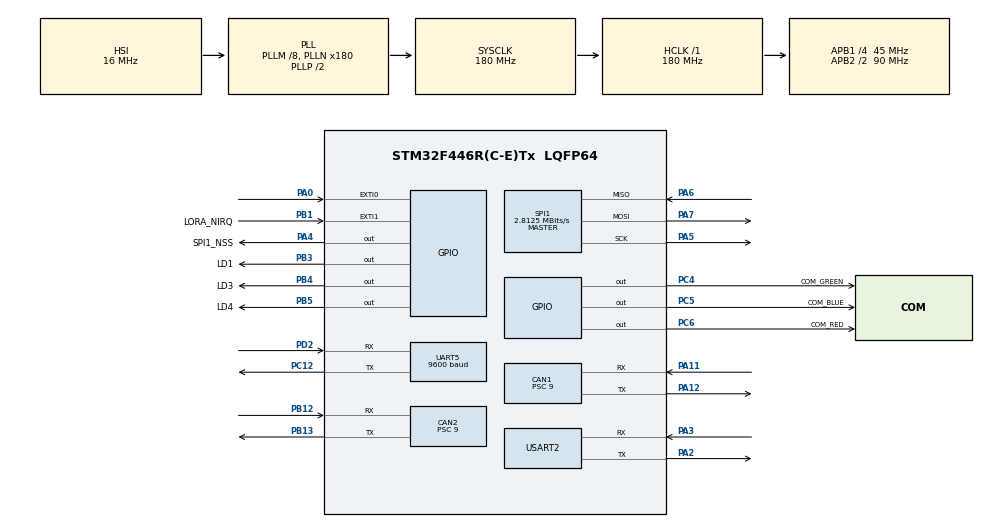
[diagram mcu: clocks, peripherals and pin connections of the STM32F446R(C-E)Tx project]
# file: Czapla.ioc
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Mcu.Family=STM32F4
PA6.Mode=Full_Duplex_Master
PH0-OSC_IN.Signal=RCC_OSC_IN
RCC.CortexFreq_Value=180000000
Dma.SPI1_RX.1.Mode=DMA_NORMAL
Dma.SPI1_RX.1.FIFOMode=DMA_FIFOMODE_ENABLE
SPI1.VirtualType=VM_MASTER
Dma.SPI1_RX.1.FIFOThreshold=DMA_FIFO_THRESHOLD_FULL
PC12.Signal=UART5_TX
PA14.GPIO_Label=TCK
Dma.UART5_RX.0.FIFOMode=DMA_FIFOMODE_DISABLE
PC6.GPIO_Label=COM_RED
PA11.Mode=Master
PB13.Signal=CAN2_TX
RCC.SYSCLKSource=RCC_SYSCLKSOURCE_PLLCLK
ProjectManager.StackSize=0x400
VP_TIM1_VS_no_output1.Mode=Output Compare1 No Output
PA12.Signal=CAN1_TX
TIM1.Prescaler=44999
Dma.SPI1_RX.1.PeriphInc=DMA_PINC_DISABLE
SPI1.Direction=SPI_DIRECTION_2LINES
RCC.HCLKFreq_Value=180000000
RCC.APB2TimFreq_Value=180000000
Dma.UART5_RX.0.Priority=DMA_PRIORITY_LOW
SPI1.CalculateBaudRate=2.8125 MBits/s
UART5.OverSampling=UART_OVERSAMPLING_8
RCC.AHBFreq_Value=180000000
PH0-OSC_IN.Mode=HSE-External-Oscillator
RCC.HSE_VALUE=8000000
NVIC.TIM8_TRG_COM_TIM14_IRQn=true\:0\:0\:false\:false\:true\:false\:true
Dma.SPI1_RX.1.Priority=DMA_PRIORITY_LOW
PC14-OSC32_IN.Mode=LSE-External-Oscillator
PC4.GPIO_Label=COM_GREEN
PA14.Mode=Serial_Wire
CAN2.Prescaler=9
Dma.UART5_RX.0.MemDataAlignment=DMA_MDATAALIGN_BYTE
PB1.GPIO_Label=LORA_NIRQ
VP_SYS_VS_tim14.Mode=TIM14
Dma.SPI1_RX.1.MemBurst=DMA_MBURST_SINGLE
VP_TIM1_VS_ClockSourceINT.Mode=Internal
Dma.SPI1_RX.1.Direction=DMA_PERIPH_TO_MEMORY
RCC.FLatency-AdvancedSettings=FLASH_LATENCY_5
PH1-OSC_OUT.Mode=HSE-External-Oscillator
CAN1.Prescaler=9
Mcu.Package=LQFP64
PB1.Signal=GPXTI1
PA6.Signal=SPI1_MISO
PB12.Mode=Slave
NVIC.TimeBase=TIM8_TRG_COM_TIM14_IRQn
TIM1.Pulse-Output\ Compare1\ No\ Output=Ttransfer-1
CAN2.BS1=CAN_BS1_6TQ
CAN2.BS2=CAN_BS2_6TQ
USART2.VirtualMode=VM_ASYNC
NVIC.TimeBaseIP=TIM14
RCC.APB2CLKDivider=RCC_HCLK_DIV2
PB5.GPIO_Label=LD4
NVIC.DMA2_Stream2_IRQn=true\:0\:0\:false\:false\:true\:false\:true
Dma.Request1=SPI1_RX
RCC.APB1TimFreq_Value=90000000
NVIC.DMA1_Stream0_IRQn=true\:0\:0\:false\:false\:true\:false\:true
UART5.BaudRate=9600
PC5.Signal=GPIO_Output
TIM1.Period=2*Ttransfer+2*Tswap-1
PB13.Mode=Slave
Dma.Request0=UART5_RX
SPI1.BaudRatePrescaler=SPI_BAUDRATEPRESCALER_32
Dma.SPI1_RX.1.MemInc=DMA_MINC_ENABLE
PA4.GPIO_Label=SPI1_NSS
PB4.Signal=GPIO_Output
PA3.Signal=USART2_RX
CAN1.CalculateTimeQuantum=200.0
PA5.Mode=Full_Duplex_Master
PB3.GPIO_Label=LD1
Dma.SPI1_RX.1.Instance=DMA2_Stream2
PC15-OSC32_OUT.Mode=LSE-External-Oscillator
Dma.UART5_RX.0.MemInc=DMA_MINC_ENABLE
Dma.UART5_RX.0.Direction=DMA_PERIPH_TO_MEMORY
PA7.Mode=Full_Duplex_Master
Dma.SPI1_RX.1.MemDataAlignment=DMA_MDATAALIGN_BYTE
TIM1.Channel-Output\ Compare1\ No\ Output=TIM_CHANNEL_1
PC6.Signal=GPIO_Output
PC4.Signal=GPIO_Output
UART5.VirtualMode=Asynchronous
RCC.APB1CLKDivider=RCC_HCLK_DIV4
PC14-OSC32_IN.Signal=RCC_OSC32_IN
PA0-WKUP.Signal=GPXTI0
PA13.Signal=SYS_JTMS-SWDIO
PA3.Mode=Asynchronous
CAN1.BS2=CAN_BS2_6TQ
CAN1.BS1=CAN_BS1_6TQ
ProjectManager.TargetToolchain=SW4STM32
RCC.USBFreq_Value=180000000
PC15-OSC32_OUT.Signal=RCC_OSC32_OUT
PD2.Mode=Asynchronous
PA5.Signal=SPI1_SCK
Dma.UART5_RX.0.Mode=DMA_NORMAL
PC12.Mode=Asynchronous
board=NUCLEO-F446RE
RCC.VCOOutputFreq_Value=360000000
Dma.SPI1_RX.1.PeriphBurst=DMA_PBURST_SINGLE
VP_TIM13_VS_ClockSourceINT.Mode=Enable_Timer
RCC.APB2Freq_Value=90000000
PB4.GPIO_Label=LD3
SPI1.Mode=SPI_MODE_MASTER
CAN2.CalculateTimeQuantum=200.0
PH1-OSC_OUT.Signal=RCC_OSC_OUT
PA13.Mode=Serial_Wire
Dma.UART5_RX.0.PeriphDataAlignment=DMA_PDATAALIGN_BYTE
Mcu.Name=STM32F446R(C-E)Tx
PA2.Signal=USART2_TX
PA13.GPIO_Label=TMS
Dma.SPI1_RX.1.PeriphDataAlignment=DMA_PDATAALIGN_BYTE
RCC.48MHZClocksFreq_Value=84000000
PB3.Signal=GPIO_Output
PA4.Signal=GPIO_Output
RCC.SYSCLKFreq_VALUE=180000000
PB5.Signal=GPIO_Output
PA12.Mode=Master
PC5.GPIO_Label=COM_BLUE
Dma.UART5_RX.0.Instance=DMA1_Stream0
PA11.Signal=CAN1_RX
PA14.Signal=SYS_JTCK-SWCLK
ProjectManager.HeapSize=0x200
RCC.HSI_VALUE=16000000
NVIC.TIM8_UP_TIM13_IRQn=true\:0\:0\:false\:false\:true\:true\:true
NVIC.PriorityGroup=NVIC_PRIORITYGROUP_4
RCC.PLLM=8
RCC.PLLN=180
PA2.Mode=Asynchronous
Dma.UART5_RX.0.PeriphInc=DMA_PINC_DISABLE
PD2.Signal=UART5_RX
RCC.APB1Freq_Value=45000000
VP_CRC_VS_CRC.Mode=CRC_Activate
PB12.Signal=CAN2_RX
PA7.Signal=SPI1_MOSI

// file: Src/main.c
/* USER CODE BEGIN Header */
/**
  ******************************************************************************
  * @file           : main.c
  * @brief          : Main program body
  ******************************************************************************
  * @attention
  *
  * <h2><center>&copy; Copyright (c) 2020 STMicroelectronics.
  * All rights reserved.</center></h2>
  *
  * This software component is licensed by ST under BSD 3-Clause license,
  * the "License"; You may not use this file except in compliance with the
  * License. You may obtain a copy of the License at:
  *                        opensource.org/licenses/BSD-3-Clause
  *
  ******************************************************************************
  */
/* USER CODE END Header */
#include "main.h"
#include "can.h"
#include "crc.h"
#include "dma.h"
#include "spi.h"
#include "tim.h"
#include "usart.h"
#include "gpio.h"

/* USER CODE BEGIN Includes */
#include "SS_init.h"
#include "SS_platform.h"

/* USER CODE END Includes */

void SystemClock_Config(void);

int main(void)
{

  /* MCU Configuration--------------------------------------------------------*/

  /* Reset of all peripherals, Initializes the Flash interface and the Systick. */
  HAL_Init();

  /* Configure the system clock */
  SystemClock_Config();

  /* Initialize all configured peripherals */
  MX_GPIO_Init();
  MX_DMA_Init();
  MX_TIM13_Init();
  MX_USART2_UART_Init();
  MX_CRC_Init();
  MX_UART5_Init();
  MX_CAN1_Init();
  MX_CAN2_Init();
  MX_SPI1_Init();
  MX_TIM1_Init();
  /* USER CODE BEGIN 2 */
  SS_platform_init();
  SS_init();

  /* USER CODE END 2 */

  /* Infinite loop */
  while (1)
  {

  }
}

void SystemClock_Config(void)
{
  RCC_OscInitTypeDef RCC_OscInitStruct = {0};
  RCC_ClkInitTypeDef RCC_ClkInitStruct = {0};

  /** Configure the main internal regulator output voltage
  */
  __HAL_RCC_PWR_CLK_ENABLE();
  __HAL_PWR_VOLTAGESCALING_CONFIG(PWR_REGULATOR_VOLTAGE_SCALE1);
  /** Initializes the RCC Oscillators according to the specified parameters
  * in the RCC_OscInitTypeDef structure.
  */
  RCC_OscInitStruct.OscillatorType = RCC_OSCILLATORTYPE_HSI;
  RCC_OscInitStruct.HSIState = RCC_HSI_ON;
  RCC_OscInitStruct.HSICalibrationValue = RCC_HSICALIBRATION_DEFAULT;
  RCC_OscInitStruct.PLL.PLLState = RCC_PLL_ON;
  RCC_OscInitStruct.PLL.PLLSource = RCC_PLLSOURCE_HSI;
  RCC_OscInitStruct.PLL.PLLM = 8;
  RCC_OscInitStruct.PLL.PLLN = 180;
  RCC_OscInitStruct.PLL.PLLP = RCC_PLLP_DIV2;
  RCC_OscInitStruct.PLL.PLLQ = 2;
  RCC_OscInitStruct.PLL.PLLR = 2;
  if (HAL_RCC_OscConfig(&RCC_OscInitStruct) != HAL_OK)
  {
    Error_Handler();
  }
  /** Activate the Over-Drive mode
  */
  if (HAL_PWREx_EnableOverDrive() != HAL_OK)
  {
    Error_Handler();
  }
  /** Initializes the CPU, AHB and APB buses clocks
  */
  RCC_ClkInitStruct.ClockType = RCC_CLOCKTYPE_HCLK|RCC_CLOCKTYPE_SYSCLK
                              |RCC_CLOCKTYPE_PCLK1|RCC_CLOCKTYPE_PCLK2;
  RCC_ClkInitStruct.SYSCLKSource = RCC_SYSCLKSOURCE_PLLCLK;
  RCC_ClkInitStruct.AHBCLKDivider = RCC_SYSCLK_DIV1;
  RCC_ClkInitStruct.APB1CLKDivider = RCC_HCLK_DIV4;
  RCC_ClkInitStruct.APB2CLKDivider = RCC_HCLK_DIV2;

  if (HAL_RCC_ClockConfig(&RCC_ClkInitStruct, FLASH_LATENCY_5) != HAL_OK)
  {
    Error_Handler();
  }
}

void HAL_TIM_PeriodElapsedCallback(TIM_HandleTypeDef *htim)
{
  /* USER CODE BEGIN Callback 0 */
    if (htim->Instance == TIM1)
    {
        /*
		uint8_t data[10] =
		{ 't', 'e', 's', 't', 'G', 0, 0, 'x', '\r', '\n' };
		static uint8_t j = 0, d = 0;
		data[6] = j + 48;
		data[5] = d + 48;
		j++;
		if (j == 10)
		{
			j = 0;
			d++;
		}
		if (d == 10)
			d = 0;
		//HAL_GPIO_TogglePin (COM_BLUE_GPIO_Port, COM_BLUE_Pin);
		union FRAME tx_frame;
		tx_frame.frame.type = 0x15;
		tx_frame.frame.id = 95;
		tx_frame.frame.data = 100;
		tx_frame.frame.crc = 0x00;
		tx_frame.frame.crc = HAL_CRC_Calculate(&hcrc, tx_frame.data_u32_u16.data_u32, 2);
		if(SS_grazyna_get_from_fifo_tx(&tx_frame) !=-1)
			RFM23_send(tx_frame.data_u8.data);
        */
        //HAL_GPIO_TogglePin(LD4_GPIO_Port, LD4_Pin);
    }
  /* USER CODE END Callback 0 */
  if (htim->Instance == TIM14) {
    HAL_IncTick();
  }
}

void Error_Handler(void)
{
}

/************************ (C) COPYRIGHT STMicroelectronics *****END OF FILE****/
